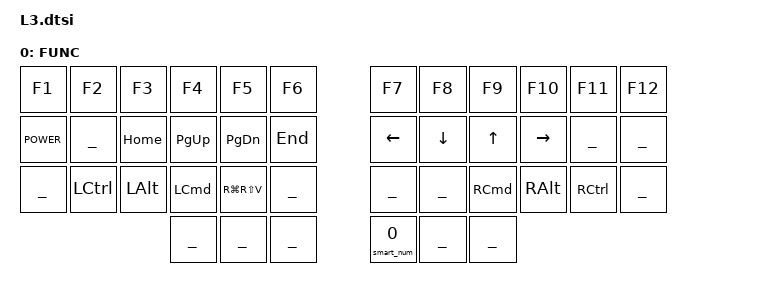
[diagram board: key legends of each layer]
/ {
	keymap {
		compatible = "zmk,keymap";

		Function {
			label = "FUNC";
			bindings = <
		// ╭───────────────┬───────────────┬───────────────┬───────────────┬───────────────┬───────────────╮   ╭───────────────┬───────────────┬───────────────┬───────────────┬───────────────┬───────────────╮
		//  0               1               2               3               4               5                   6               7               8               9               10              11
		 	&kp F1          &kp F2          &kp F3          &kp F4          &kp F5	        &kp F6              &kp F7          &kp F8          &kp F9          &kp F10         &kp F11         &kp F12
		// ├───────────────├───────────────┼───────────────┼───────────────┼───────────────┼───────────────┤   ├───────────────├───────────────┼───────────────┼───────────────┼───────────────┼───────────────┤
		//  12              13              14              15              16              17                  18              19              20              21              22              23
		    &kp C_POWER     ___            &kp HOME        &kp PAGE_UP     &kp PAGE_DOWN    &kp END             &kp LEFT        &kp DOWN        &kp UP          &kp RIGHT       ___             ___
		// ├───────────────├───────────────┼───────────────┼───────────────┼───────────────┼───────────────┤   ├───────────────├───────────────┼───────────────┼───────────────┼───────────────┼───────────────┤
		//  24              25              26              27              28              29                  30              31              32              33              34              35
			___             &kp LCTRL       &kp LALT        &kp LCMD       &kp RG(RS(V))    ___                 ___             ___             &kp RCMD        &kp RALT        &kp RCTRL       ___
		// ╰───────────────┴───────────────┴───────────────┼───────────────┼───────────────┼───────────────┤   ├───────────────├───────────────┼───────────────┼───────────────┴───────────────┴───────────────╯
		//                                                  36              37              38                  39              40              41
															___             ___             ___	               	&smart_num 0    ___             ___
		//                                                 ╰───────────────┴───────────────┴───────────────╯   ╰───────────────┴───────────────┴───────────────╯
			>;
		};
	};
};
